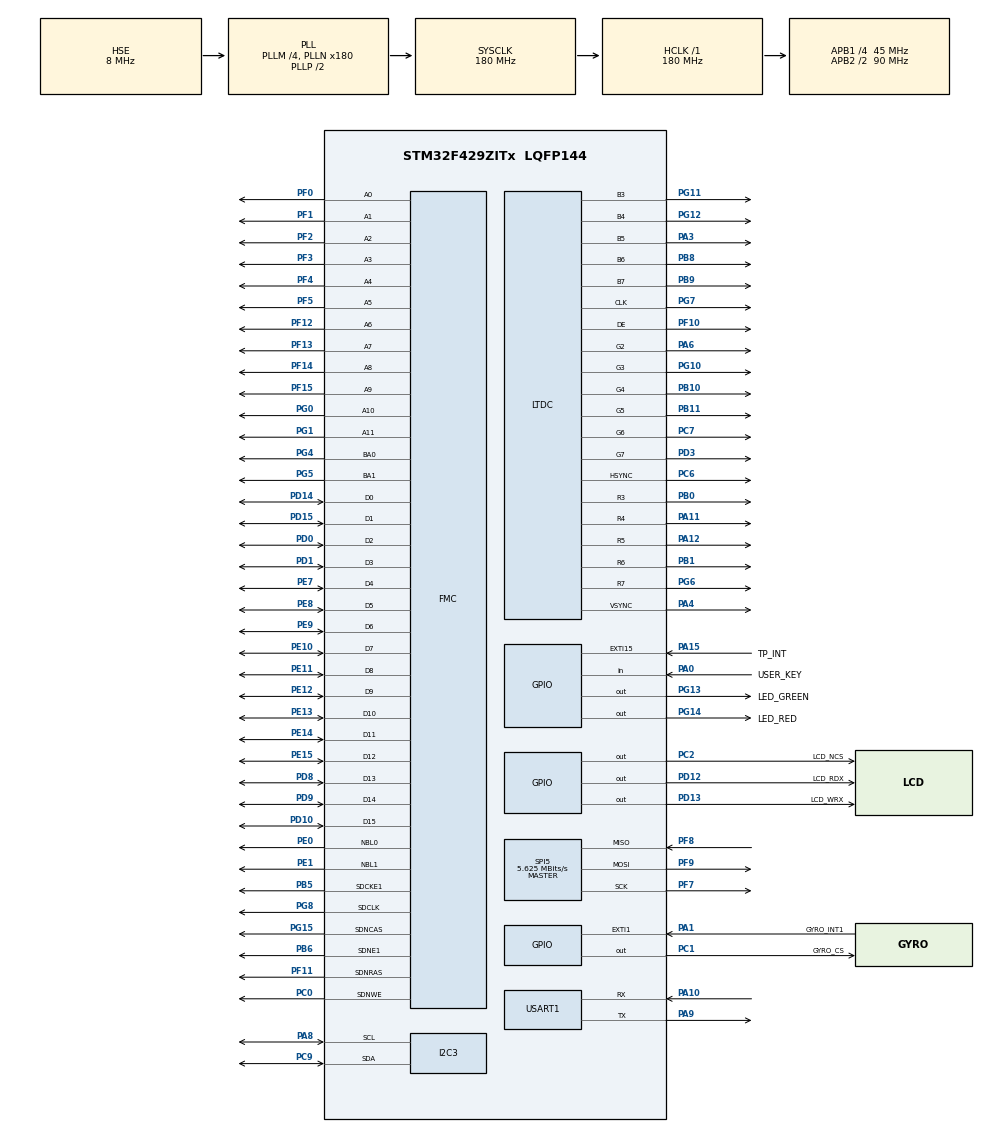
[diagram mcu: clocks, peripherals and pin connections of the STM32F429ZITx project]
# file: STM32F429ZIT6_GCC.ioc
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DMA2D.ColorMode=DMA2D_OUTPUT_RGB565
Dma.Request0=USART1_RX
Dma.Request1=USART1_TX
Dma.USART1_RX.0.Direction=DMA_PERIPH_TO_MEMORY
Dma.USART1_RX.0.FIFOMode=DMA_FIFOMODE_DISABLE
Dma.USART1_RX.0.Instance=DMA2_Stream2
Dma.USART1_RX.0.MemDataAlignment=DMA_MDATAALIGN_BYTE
Dma.USART1_RX.0.MemInc=DMA_MINC_ENABLE
Dma.USART1_RX.0.Mode=DMA_NORMAL
Dma.USART1_RX.0.PeriphDataAlignment=DMA_PDATAALIGN_BYTE
Dma.USART1_RX.0.PeriphInc=DMA_PINC_DISABLE
Dma.USART1_RX.0.Priority=DMA_PRIORITY_LOW
Dma.USART1_TX.1.Direction=DMA_MEMORY_TO_PERIPH
Dma.USART1_TX.1.FIFOMode=DMA_FIFOMODE_DISABLE
Dma.USART1_TX.1.Instance=DMA2_Stream7
Dma.USART1_TX.1.MemDataAlignment=DMA_MDATAALIGN_BYTE
Dma.USART1_TX.1.MemInc=DMA_MINC_ENABLE
Dma.USART1_TX.1.Mode=DMA_NORMAL
Dma.USART1_TX.1.PeriphDataAlignment=DMA_PDATAALIGN_BYTE
Dma.USART1_TX.1.PeriphInc=DMA_PINC_DISABLE
Dma.USART1_TX.1.Priority=DMA_PRIORITY_LOW
FMC.CASLatency1=FMC_SDRAM_CAS_LATENCY_3
FMC.ExitSelfRefreshDelay1=7
FMC.LoadToActiveDelay1=2
FMC.RCDDelay1=2
FMC.RPDelay1=2
FMC.ReadBurst1=FMC_SDRAM_RBURST_ENABLE
FMC.ReadPipeDelay1=FMC_SDRAM_RPIPE_DELAY_1
FMC.RowCycleDelay1=7
FMC.RowCycleDelay2=7
FMC.SDClockPeriod1=FMC_SDRAM_CLOCK_PERIOD_2
FMC.SelfRefreshTime1=4
FMC.WriteRecoveryTime1=3
I2C3.I2C_Mode=I2C_Fast
LTDC.ActiveH=320
LTDC.ActiveW=240
LTDC.Alpha0_L0=0
LTDC.Alpha0_L1=255
LTDC.Alpha_L0=255
LTDC.Alpha_L1=255
LTDC.BlendingFactor1_L0=LTDC_BLENDING_FACTOR1_PAxCA
LTDC.BlendingFactor1_L1=LTDC_BLENDING_FACTOR1_PAxCA
LTDC.BlendingFactor2_L0=LTDC_BLENDING_FACTOR2_PAxCA
LTDC.BlendingFactor2_L1=LTDC_BLENDING_FACTOR2_PAxCA
LTDC.Blue_L0=0
LTDC.FBStartAdress_L0=0xD0000000
LTDC.FBStartAdress_L1=0xD0096000
LTDC.HBP=20
LTDC.HFP=10
LTDC.HSync=10
LTDC.ImageHeight_L0=320
LTDC.ImageHeight_L1=320
LTDC.ImageWidth_L0=240
LTDC.ImageWidth_L1=240
LTDC.Layers=0
LTDC.PixelFormat_L0=LTDC_PIXEL_FORMAT_RGB565
LTDC.Red=0
LTDC.VFP=4
LTDC.VSync=2
LTDC.WindowX0_L0=0
LTDC.WindowX0_L1=0
LTDC.WindowX1_L0=240
LTDC.WindowX1_L1=240
LTDC.WindowY0_L0=0
LTDC.WindowY0_L1=0
LTDC.WindowY1_L0=320
LTDC.WindowY1_L1=320
Mcu.Family=STM32F4
Mcu.Name=STM32F429ZITx
Mcu.Package=LQFP144
NVIC.DMA2D_IRQn=true\:6\:0\:true\:false\:true\:true\:true\:true
NVIC.DMA2_Stream2_IRQn=true\:2\:0\:true\:false\:true\:false\:true\:true
NVIC.DMA2_Stream7_IRQn=true\:2\:0\:true\:false\:true\:false\:true\:true
NVIC.EXTI15_10_IRQn=true\:5\:0\:true\:false\:true\:true\:true\:true
NVIC.EXTI1_IRQn=true\:5\:0\:true\:false\:true\:true\:true\:true
NVIC.PriorityGroup=NVIC_PRIORITYGROUP_4
NVIC.TIM6_DAC_IRQn=true\:0\:0\:true\:false\:true\:false\:true\:true
NVIC.TimeBase=TIM6_DAC_IRQn
NVIC.TimeBaseIP=TIM6
NVIC.USART1_IRQn=true\:6\:0\:true\:false\:true\:true\:true\:true
PA0/WKUP.GPIO_Label=USER_KEY
PA0/WKUP.GPIO_PuPd=GPIO_NOPULL
PA0/WKUP.Signal=GPIO_Input
PA1.GPIO_Label=GYRO_INT1
PA1.GPIO_ModeDefaultEXTI=GPIO_MODE_IT_RISING
PA1.GPIO_PuPd=GPIO_PULLDOWN
PA1.Signal=GPXTI1
PA10.Mode=Asynchronous
PA10.Signal=USART1_RX
PA11.Mode=RGB565
PA11.Signal=LTDC_R4
PA12.Mode=RGB565
PA12.Signal=LTDC_R5
PA13.Mode=Serial_Wire
PA13.Signal=SYS_JTMS-SWDIO
PA14.Mode=Serial_Wire
PA14.Signal=SYS_JTCK-SWCLK
PA15.GPIO_Label=TP_INT
PA15.GPIO_ModeDefaultEXTI=GPIO_MODE_IT_FALLING
PA15.GPIO_PuPd=GPIO_PULLUP
PA15.Signal=GPXTI15
PA3.Mode=RGB565
PA3.Signal=LTDC_B5
PA4.Mode=RGB565
PA4.Signal=LTDC_VSYNC
PA6.Mode=RGB565
PA6.Signal=LTDC_G2
PA8.Mode=I2C
PA8.Signal=I2C3_SCL
PA9.Mode=Asynchronous
PA9.Signal=USART1_TX
PB0.Mode=RGB565
PB0.Signal=LTDC_R3
PB1.Mode=RGB565
PB1.Signal=LTDC_R6
PB10.Mode=RGB565
PB10.Signal=LTDC_G4
PB11.Mode=RGB565
PB11.Signal=LTDC_G5
PB5.Mode=SdramChipSelect2_1
PB5.Signal=FMC_SDCKE1
PB6.Mode=SdramChipSelect2_1
PB6.Signal=FMC_SDNE1
PB8.Mode=RGB565
PB8.Signal=LTDC_B6
PB9.Mode=RGB565
PB9.Signal=LTDC_B7
PC0.Signal=FMC_SDNWE
PC1.GPIO_Label=GYRO_CS
PC1.GPIO_Speed=GPIO_SPEED_FREQ_VERY_HIGH
PC1.Signal=GPIO_Output
PC2.GPIO_Label=LCD_NCS
PC2.GPIO_Speed=GPIO_SPEED_FREQ_VERY_HIGH
PC2.Signal=GPIO_Output
PC6.Mode=RGB565
PC6.Signal=LTDC_HSYNC
PC7.Mode=RGB565
PC7.Signal=LTDC_G6
PC9.Mode=I2C
PC9.Signal=I2C3_SDA
PD0.Signal=FMC_D2_DA2
PD1.Signal=FMC_D3_DA3
PD10.Signal=FMC_D15_DA15
PD12.GPIO_Label=LCD_RDX
PD12.GPIO_Speed=GPIO_SPEED_FREQ_VERY_HIGH
PD12.Signal=GPIO_Output
PD13.GPIO_Label=LCD_WRX
PD13.GPIO_Speed=GPIO_SPEED_FREQ_VERY_HIGH
PD13.Signal=GPIO_Output
PD14.Signal=FMC_D0_DA0
PD15.Signal=FMC_D1_DA1
PD3.Mode=RGB565
PD3.Signal=LTDC_G7
PD8.Signal=FMC_D13_DA13
PD9.Signal=FMC_D14_DA14
PE0.Signal=FMC_NBL0
PE1.Signal=FMC_NBL1
PE10.Signal=FMC_D7_DA7
PE11.Signal=FMC_D8_DA8
PE12.Signal=FMC_D9_DA9
PE13.Signal=FMC_D10_DA10
PE14.Signal=FMC_D11_DA11
PE15.Signal=FMC_D12_DA12
PE7.Signal=FMC_D4_DA4
PE8.Signal=FMC_D5_DA5
PE9.Signal=FMC_D6_DA6
PF0.Signal=FMC_A0
PF1.Signal=FMC_A1
PF10.Mode=RGB565
PF10.Signal=LTDC_DE
PF11.Signal=FMC_SDNRAS
PF12.Signal=FMC_A6
PF13.Signal=FMC_A7
PF14.Signal=FMC_A8
PF15.Signal=FMC_A9
PF2.Signal=FMC_A2
PF3.Signal=FMC_A3
PF4.Signal=FMC_A4
PF5.Signal=FMC_A5
PF7.Mode=Full_Duplex_Master
PF7.Signal=SPI5_SCK
PF8.Mode=Full_Duplex_Master
PF8.Signal=SPI5_MISO
PF9.Mode=Full_Duplex_Master
PF9.Signal=SPI5_MOSI
PG0.Signal=FMC_A10
PG1.Signal=FMC_A11
PG10.Mode=RGB565
PG10.Signal=LTDC_G3
PG11.Mode=RGB565
PG11.Signal=LTDC_B3
PG12.Mode=RGB565
PG12.Signal=LTDC_B4
PG13.GPIO_Label=LED_GREEN
PG13.PinState=GPIO_PIN_RESET
PG13.Signal=GPIO_Output
PG14.GPIO_Label=LED_RED
PG14.PinState=GPIO_PIN_RESET
PG14.Signal=GPIO_Output
PG15.Signal=FMC_SDNCAS
PG4.Signal=FMC_A14_BA0
PG5.Signal=FMC_A15_BA1
PG6.Mode=RGB565
PG6.Signal=LTDC_R7
PG7.Mode=RGB565
PG7.Signal=LTDC_CLK
PG8.Signal=FMC_SDCLK
PH0/OSC_IN.Mode=HSE-External-Oscillator
PH0/OSC_IN.Signal=RCC_OSC_IN
PH1/OSC_OUT.Mode=HSE-External-Oscillator
PH1/OSC_OUT.Signal=RCC_OSC_OUT
ProjectManager.HeapSize=0x200
ProjectManager.StackSize=0x400
ProjectManager.TargetToolchain=CMake
RCC.48MHZClocksFreq_Value=45000000
RCC.AHBFreq_Value=180000000
RCC.APB1CLKDivider=RCC_HCLK_DIV4
RCC.APB1Freq_Value=45000000
RCC.APB1TimFreq_Value=90000000
RCC.APB2CLKDivider=RCC_HCLK_DIV2
RCC.APB2Freq_Value=90000000
RCC.APB2TimFreq_Value=180000000
RCC.CortexFreq_Value=180000000
RCC.EnbaleCSS=true
RCC.HCLKFreq_Value=180000000
RCC.HSE_VALUE=8000000
RCC.HSI_VALUE=16000000
RCC.LSE_VALUE=32768
RCC.PLLM=4
RCC.PLLN=180
RCC.PLLQ=8
RCC.PLLSAIDivR=RCC_PLLSAIDIVR_4
RCC.PLLSAIN=50
RCC.PLLSAIR=4
RCC.PLLSourceVirtual=RCC_PLLSOURCE_HSE
RCC.SYSCLKFreq_VALUE=180000000
RCC.SYSCLKSource=RCC_SYSCLKSOURCE_PLLCLK
RCC.VCOOutputFreq_Value=360000000
SH.FMC_A0.0=FMC_A0,12b-sda1
SH.FMC_A1.0=FMC_A1,12b-sda1
SH.FMC_A10.0=FMC_A10,12b-sda1
SH.FMC_A11.0=FMC_A11,12b-sda1
SH.FMC_A14_BA0.0=FMC_BA0,FourSdramBanks1
SH.FMC_A15_BA1.0=FMC_BA1,FourSdramBanks1
SH.FMC_A2.0=FMC_A2,12b-sda1
SH.FMC_A3.0=FMC_A3,12b-sda1
SH.FMC_A4.0=FMC_A4,12b-sda1
SH.FMC_A5.0=FMC_A5,12b-sda1
SH.FMC_A6.0=FMC_A6,12b-sda1
SH.FMC_A7.0=FMC_A7,12b-sda1
SH.FMC_A8.0=FMC_A8,12b-sda1
SH.FMC_A9.0=FMC_A9,12b-sda1
SH.FMC_D0_DA0.0=FMC_D0,sd-16b-d1
SH.FMC_D10_DA10.0=FMC_D10,sd-16b-d1
SH.FMC_D11_DA11.0=FMC_D11,sd-16b-d1
SH.FMC_D12_DA12.0=FMC_D12,sd-16b-d1
SH.FMC_D13_DA13.0=FMC_D13,sd-16b-d1
SH.FMC_D14_DA14.0=FMC_D14,sd-16b-d1
SH.FMC_D15_DA15.0=FMC_D15,sd-16b-d1
SH.FMC_D1_DA1.0=FMC_D1,sd-16b-d1
SH.FMC_D2_DA2.0=FMC_D2,sd-16b-d1
SH.FMC_D3_DA3.0=FMC_D3,sd-16b-d1
SH.FMC_D4_DA4.0=FMC_D4,sd-16b-d1
SH.FMC_D5_DA5.0=FMC_D5,sd-16b-d1
SH.FMC_D6_DA6.0=FMC_D6,sd-16b-d1
SH.FMC_D7_DA7.0=FMC_D7,sd-16b-d1
SH.FMC_D8_DA8.0=FMC_D8,sd-16b-d1
SH.FMC_D9_DA9.0=FMC_D9,sd-16b-d1
SH.FMC_NBL0.0=FMC_NBL0,Sd2ByteEnable1
SH.FMC_NBL1.0=FMC_NBL1,Sd2ByteEnable1
SH.FMC_SDCLK.0=FMC_SDCLK,12b-sda1
SH.FMC_SDNCAS.0=FMC_SDNCAS,12b-sda1
SH.FMC_SDNRAS.0=FMC_SDNRAS,12b-sda1
SH.FMC_SDNWE.0=FMC_SDNWE,12b-sda1
SPI5.BaudRatePrescaler=SPI_BAUDRATEPRESCALER_16
SPI5.CalculateBaudRate=5.625 MBits/s
SPI5.Direction=SPI_DIRECTION_2LINES
SPI5.Mode=SPI_MODE_MASTER
SPI5.VirtualType=VM_MASTER
STMicroelectronics.X-CUBE-ALGOBUILD.1.4.0.LibraryCcDSPOoLibraryJjDSPOoLibrary=true
TIM2.Prescaler=180 - 1
USART1.VirtualMode=VM_ASYNC
VP_DMA2D_VS_DMA2D.Mode=DMA2D_Activate
VP_STMicroelectronics.X-CUBE-ALGOBUILD_VS_DSPOoLibraryJjLibrary_1.4.0_1.4.0.Mode=DSPOoLibraryJjLibrary
VP_SYS_VS_tim6.Mode=TIM6
VP_TIM2_VS_ClockSourceINT.Mode=Internal
board=custom

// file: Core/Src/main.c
/* USER CODE BEGIN Header */
/**
  ******************************************************************************
  * @file           : main.c
  * @brief          : Main program body
  ******************************************************************************
  * @attention
  *
  * Copyright (c) 2026 STMicroelectronics.
  * All rights reserved.
  *
  * This software is licensed under terms that can be found in the LICENSE file
  * in the root directory of this software component.
  * If no LICENSE file comes with this software, it is provided AS-IS.
  *
  ******************************************************************************
  */
/* USER CODE END Header */
#include "main.h"
#include "dma.h"
#include "dma2d.h"
#include "i2c.h"
#include "ltdc.h"
#include "spi.h"
#include "tim.h"
#include "usart.h"
#include "gpio.h"
#include "fmc.h"

void SystemClock_Config(void);
/* USER CODE BEGIN PFP */
extern void ek_main(void);
/* USER CODE END PFP */

int main(void)
{

  /* MCU Configuration--------------------------------------------------------*/

  /* Reset of all peripherals, Initializes the Flash interface and the Systick. */
  HAL_Init();

  /* Configure the system clock */
  SystemClock_Config();

  /* Initialize all configured peripherals */
  MX_GPIO_Init();
  MX_DMA_Init();
  MX_USART1_UART_Init();
  MX_LTDC_Init();
  MX_FMC_Init();
  MX_SPI5_Init();
  MX_I2C3_Init();
  MX_DMA2D_Init();
  MX_TIM2_Init();
  /* USER CODE BEGIN 2 */
    ek_main();
  /* USER CODE END 2 */

  /* Infinite loop */
    while (1)
    {

    }
}

void SystemClock_Config(void)
{
  RCC_OscInitTypeDef RCC_OscInitStruct = {0};
  RCC_ClkInitTypeDef RCC_ClkInitStruct = {0};

  /** Configure the main internal regulator output voltage
  */
  __HAL_RCC_PWR_CLK_ENABLE();
  __HAL_PWR_VOLTAGESCALING_CONFIG(PWR_REGULATOR_VOLTAGE_SCALE1);

  /** Initializes the RCC Oscillators according to the specified parameters
  * in the RCC_OscInitTypeDef structure.
  */
  RCC_OscInitStruct.OscillatorType = RCC_OSCILLATORTYPE_HSE;
  RCC_OscInitStruct.HSEState = RCC_HSE_ON;
  RCC_OscInitStruct.PLL.PLLState = RCC_PLL_ON;
  RCC_OscInitStruct.PLL.PLLSource = RCC_PLLSOURCE_HSE;
  RCC_OscInitStruct.PLL.PLLM = 4;
  RCC_OscInitStruct.PLL.PLLN = 180;
  RCC_OscInitStruct.PLL.PLLP = RCC_PLLP_DIV2;
  RCC_OscInitStruct.PLL.PLLQ = 8;
  if (HAL_RCC_OscConfig(&RCC_OscInitStruct) != HAL_OK)
  {
    Error_Handler();
  }

  /** Activate the Over-Drive mode
  */
  if (HAL_PWREx_EnableOverDrive() != HAL_OK)
  {
    Error_Handler();
  }

  /** Initializes the CPU, AHB and APB buses clocks
  */
  RCC_ClkInitStruct.ClockType = RCC_CLOCKTYPE_HCLK|RCC_CLOCKTYPE_SYSCLK
                              |RCC_CLOCKTYPE_PCLK1|RCC_CLOCKTYPE_PCLK2;
  RCC_ClkInitStruct.SYSCLKSource = RCC_SYSCLKSOURCE_PLLCLK;
  RCC_ClkInitStruct.AHBCLKDivider = RCC_SYSCLK_DIV1;
  RCC_ClkInitStruct.APB1CLKDivider = RCC_HCLK_DIV4;
  RCC_ClkInitStruct.APB2CLKDivider = RCC_HCLK_DIV2;

  if (HAL_RCC_ClockConfig(&RCC_ClkInitStruct, FLASH_LATENCY_5) != HAL_OK)
  {
    Error_Handler();
  }

  /** Enables the Clock Security System
  */
  HAL_RCC_EnableCSS();
}

void HAL_TIM_PeriodElapsedCallback(TIM_HandleTypeDef *htim)
{
  if (htim->Instance == TIM6)
  {
    HAL_IncTick();
  }
}

void Error_Handler(void)
{
    __disable_irq();
    while (1)
    {
    }
}
